AUTOSAR XML (schema 00051)
package /adcm/AdaptiveApplicationSwComponentTypes
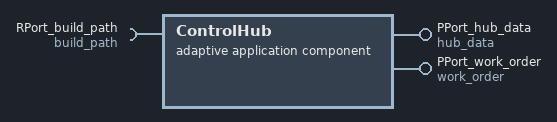
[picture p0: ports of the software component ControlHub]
  adaptive application sw component type ControlHub
    provide port PPort_hub_data: provided-interface=hub_data
    provide port PPort_work_order: provided-interface=work_order
    require port RPort_build_path: required-interface=build_path
package /adcm/Executables
  executable ControlHub: category=APPLICATION_LEVEL, minimum-timer-granularity=1000
    root sw component prototype ControlHub: application-type=ControlHub
